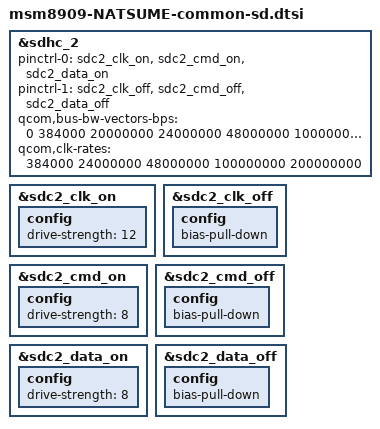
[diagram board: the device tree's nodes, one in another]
/*
 * This software is contributed or developed by KYOCERA Corporation.
 * (C) 2019 KYOCERA Corporation
 *
 * This program is free software; you can redistribute it and/or modify
 * it under the terms of the GNU General Public License version 2 and
 * only version 2 as published by the Free Software Foundation.
 *
 * This program is distributed in the hope that it will be useful,
 * but WITHOUT ANY WARRANTY; without even the implied warranty of
 * MERCHANTABILITY or FITNESS FOR A PARTICULAR PURPOSE.  See the
 * GNU General Public License for more details.
 */

&sdhc_2 {
	/delete-property/ cd-gpios;
	pinctrl-0 = <&sdc2_clk_on &sdc2_cmd_on &sdc2_data_on>; 
	pinctrl-1 = <&sdc2_clk_off &sdc2_cmd_off &sdc2_data_off>;

	qcom,bus-bw-vectors-bps = <0 384000 20000000 24000000 48000000
				100000000 200000000 4294967295>;

	qcom,clk-rates = <384000 24000000 48000000 100000000 200000000>;
};

&sdc2_clk_on {
	config {
		drive-strength = <12>; /* 12 MA */
	};
};

&sdc2_clk_off {
	config {
		/delete-property/ bias-disable;
		bias-pull-down;
	};
};

&sdc2_cmd_on {
	config {
		drive-strength = <8>; /* 8 MA */
	};
};

&sdc2_cmd_off {
	config {
		/delete-property/ bias-pull-up;
		bias-pull-down;
	};
};

&sdc2_data_on {
	config {
		drive-strength = <8>; /* 10 MA */
	};
};

&sdc2_data_off {
	config {
		/delete-property/ bias-pull-up;
		bias-pull-down;
	};
};


